# STM32H7B0 register map
File version: 2.3
CPU: CM7 r0p1, little endian, MPU, FPU, 4 interrupt priority bits
Registers are 32-bit, read-write, reset 0x0 unless marked. A register's access mark holds for its fields unless they carry their own. Offsets are from the block's base; [hi:lo] are bit positions; 'fields as' and 'values as' point back to an identical list.

## RCC (part 1 of 3) — Reset and clock control
Base 0x58024400
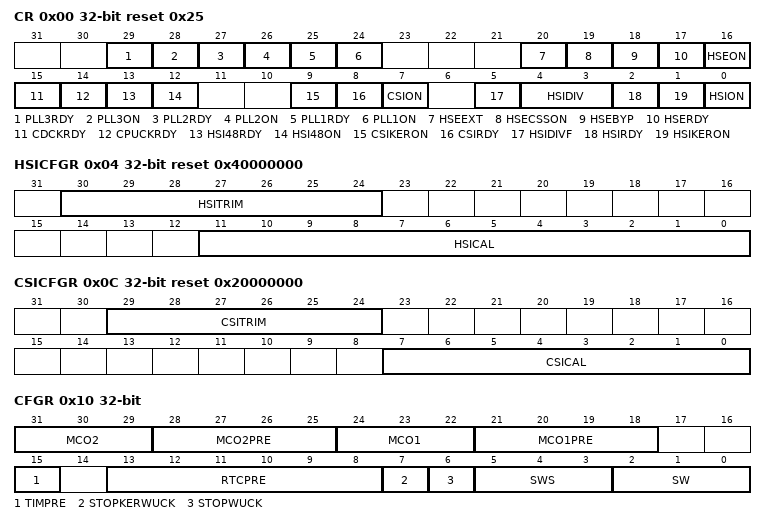
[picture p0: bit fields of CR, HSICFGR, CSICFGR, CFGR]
0x00 CR access per field reset 0x25
  [29] PLL3RDY ro — PLL3 clock ready flag Set by hardware to indicate that the PLL3 is locked.
    0=NotReady (Clock not ready); 1=Ready (Clock ready)
  [28] PLL3ON rw — PLL3 enable Set and cleared by software to enable PLL3. Cleared by hardware when entering Stop or Standby mode.
    0=Off (Clock Off); 1=On (Clock On)
  [27] PLL2RDY ro — PLL2 clock ready flag Set by hardware to indicate that the PLL2 is locked.
    0=NotReady (Clock not ready); 1=Ready (Clock ready)
  [26] PLL2ON rw — PLL2 enable Set and cleared by software to enable PLL2. Cleared by hardware when entering Stop or Standby mode.
    0=Off (Clock Off); 1=On (Clock On)
  [25] PLL1RDY ro — PLL1 clock ready flag Set by hardware to indicate that the PLL1 is locked.
    0=NotReady (Clock not ready); 1=Ready (Clock ready)
  [24] PLL1ON rw — PLL1 enable Set and cleared by software to enable PLL1. Cleared by hardware when entering Stop or Standby mode. Note that the hardware prevents writing this bit to 0, if the PLL1 output is used as the system clock.
    0=Off (Clock Off); 1=On (Clock On)
  [20] HSEEXT rw — external high speed clock type in Bypass mode Set and reset by software to select the external clock type (analog or digital). The external clock must be enabled with the HSEON bit to be used by the device. The HSEEXT bit can be written only if the HSE oscillator is disabled.
  [19] HSECSSON rw — HSE clock security system enable Set by software to enable clock security system on HSE. This bit is set only (disabled by a system reset or when the system enters in Standby mode). When HSECSSON is set, the clock detector is enabled by hardware when the HSE is ready and disabled by hardware if an oscillator failure is detected.
    0=Off (Clock Off); 1=On (Clock On)
  [18] HSEBYP rw — HSE clock bypass Set and cleared by software to bypass the oscillator with an external clock. The external clock must be enabled with the HSEON bit to be used by the device. The HSEBYP bit can be written only if the HSE oscillator is disabled.
    0=NotBypassed (HSE crystal oscillator not bypassed); 1=Bypassed (HSE crystal oscillator bypassed with external clock)
  [17] HSERDY ro — HSE clock ready flag Set by hardware to indicate that the HSE oscillator is stable.
    0=NotReady (Clock not ready); 1=Ready (Clock ready)
  [16] HSEON rw — HSE clock enable Set and cleared by software. Cleared by hardware to stop the HSE when entering Stop or Standby mode. This bit cannot be cleared if the HSE is used directly (via SW mux) as system clock, or if the HSE is selected as reference clock for PLL1 with PLL1 enabled (PLL1ON bit set to 1).
    0=Off (Clock Off); 1=On (Clock On)
  [15] CDCKRDY ro — CPU domain clocks ready flag Set by hardware to indicate that the following CPU domain clocks are available: APB1, APB2, AHB bus matrix.
    0=NotReady (Clock not ready); 1=Ready (Clock ready)
  [14] CPUCKRDY ro — CPU related clocks ready flag Set by hardware to indicate that the CPU related clocks (CPU, APB3, AXI bus matrix and related memories) are available.
    0=NotReady (Clock not ready); 1=Ready (Clock ready)
  [13] HSI48RDY ro — HSI48 clock ready flag Set by hardware to indicate that the HSI48 oscillator is stable.
    0=NotReady (Clock not ready); 1=Ready (Clock ready)
  [12] HSI48ON rw — HSI48 clock enable Set by software and cleared by software or by the hardware when the system enters to Stop or Standby mode.
    0=Off (Clock Off); 1=On (Clock On)
  [9] CSIKERON rw — CSI clock enable in Stop mode Set and reset by software to force the CSI to ON, even in Stop mode, in order to be quickly available as kernel clock for some peripherals. This bit has no effect on the value of CSION.
    0=Off (Clock Off); 1=On (Clock On)
  [8] CSIRDY ro — CSI clock ready flag Set by hardware to indicate that the CSI oscillator is stable. This bit is activated only if the RC is enabled by CSION (it is not activated if the CSI is enabled by CSIKERON or by a peripheral request).
    0=NotReady (Clock not ready); 1=Ready (Clock ready)
  [7] CSION rw — CSI clock enable Set and reset by software to enable/disable CSI clock for system and/or peripheral. Set by hardware to force the CSI to ON when the system leaves Stop mode, if STOPWUCK = 1 or STOPKERWUCK = 1. This bit cannot be cleared if the CSI is used directly (via SW mux) as system clock, or if the CSI is selected as reference clock for PLL1 with PLL1 enabled (PLL1ON bit set to 1).
    0=Off (Clock Off); 1=On (Clock On)
  [5] HSIDIVF ro — HSI divider flag Set and reset by hardware. As a write operation to HSIDIV has not an immediate effect on the frequency, this flag indicates the current status of the HSI divider. HSIDIVF goes immediately to 0 when HSIDIV value is changed, and is set back to 1 when the output frequency matches the value programmed into HSIDIV. clock setting is completed)
    0=NotPropagated (New HSIDIV ratio has not yet propagated to hsi_ck); 1=Propagated (HSIDIV ratio has propagated to hsi_ck)
  [4:3] HSIDIV rw — HSI clock divider Set and reset by software. These bits allow selecting a division ratio in order to configure the wanted HSI clock frequency. The HSIDIV cannot be changed if the HSI is selected as reference clock for at least one enabled PLL (PLLxON bit set to 1). In that case, the new HSIDIV value is ignored.
    0=Div1 (No division); 1=Div2 (Division by 2); 2=Div4 (Division by 4); 3=Div8 (Division by 8)
  [2] HSIRDY ro — HSI clock ready flag Set by hardware to indicate that the HSI oscillator is stable.
    0=NotReady (Clock not ready); 1=Ready (Clock ready)
  [1] HSIKERON rw — HSI clock enable in Stop mode Set and reset by software to force the HSI to ON, even in Stop mode, in order to be quickly available as kernel clock for peripherals. This bit has no effect on the value of HSION.
    0=Off (Clock Off); 1=On (Clock On)
  [0] HSION rw — HSI clock enable Set and cleared by software. Set by hardware to force the HSI to ON when the product leaves Stop mode, if STOPWUCK = 0 or STOPKERWUCK = 0. Set by hardware to force the HSI to ON when the product leaves Standby mode or in case of a failure of the HSE which is used as the system clock source. This bit cannot be cleared if the HSI is used directly (via SW mux) as system clock, or if the HSI is selected as reference clock for PLL1 with PLL1 enabled (PLL1ON bit set to 1).
    0=Off (Clock Off); 1=On (Clock On)
0x04 HSICFGR access per field reset 0x40000000 (reset mask 0xFFFFF000) — RCC HSI calibration register
  [30:24] HSITRIM rw — HSI clock trimming Set by software to adjust calibration. HSITRIM field is added to the engineering option bytes loaded during reset phase (FLASH_HSI_opt) in order to form the calibration trimming value. HSICAL=HSITRIM+FLASH_HSI_opt. Note: The reset value of the field is 0x40.
  [11:0] HSICAL ro — HSI clock calibration Set by hardware by option byte loading during system reset nreset. Adjusted by software through trimming bits HSITRIM. This field represents the sum of engineering option byte calibration value and HSITRIM bits value.
0x08 CRRCR ro (reset mask 0xFFFFF000) — RCC clock recovery RC register
  [9:0] HSI48CAL — Internal RC 48 MHz clock calibration Set by hardware by option byte loading during system reset nreset. Read-only.
0x0C CSICFGR access per field reset 0x20000000 (reset mask 0xFFFFF000) — RCC CSI calibration register
  [29:24] CSITRIM rw — CSI clock trimming Set by software to adjust calibration. CSITRIM field is added to the engineering option bytes loaded during reset phase (FLASH_CSI_opt) in order to form the calibration trimming value. CSICAL=CSITRIM+FLASH_CSI_opt. Note: The reset value of the field is 0x20.
  [7:0] CSICAL ro — CSI clock calibration Set by hardware by option byte loading during system reset nreset. Adjusted by software through trimming bits CSITRIM. This field represents the sum of engineering option byte calibration value and CSITRIM bits value.
0x10 CFGR access per field
  [31:29] MCO2 rw — microcontroller clock output 2 Set and cleared by software. Clock source selection may generate glitches on MCO2. It is highly recommended to configure these bits only after reset, before enabling the external oscillators and the PLLs. others: reserved
    0=SYSCLK (System clock selected for micro-controller clock output); 1=PLL2_P (pll2_p selected for micro-controller clock output); 2=HSE (HSE selected for micro-controller clock output); 3=PLL1_P (pll1_p selected for micro-controller clock output); 4=CSI (CSI selected for micro-controller clock output); 5=LSI (LSI selected for micro-controller clock output)
  [28:25] MCO2PRE rw — MCO2 prescaler Set and cleared by software to configure the prescaler of the MCO2. Modification of this prescaler may generate glitches on MCO2. It is highly recommended to change this prescaler only after reset, before enabling the external oscillators and the PLLs. ...
  [24:22] MCO1 rw — Microcontroller clock output 1 Set and cleared by software. Clock source selection may generate glitches on MCO1. It is highly recommended to configure these bits only after reset, before enabling the external oscillators and the PLLs. others: reserved
    0=HSI (HSI selected for micro-controller clock output); 1=LSE (LSE selected for micro-controller clock output); 2=HSE (HSE selected for micro-controller clock output); 3=PLL1_Q (pll1_q selected for micro-controller clock output); 4=HSI48 (HSI48 selected for micro-controller clock output)
  [21:18] MCO1PRE rw — MCO1 prescaler Set and cleared by software to configure the prescaler of the MCO1. Modification of this prescaler may generate glitches on MCO1. It is highly recommended to change this prescaler only after reset, before enabling the external oscillators and the PLLs. ...
  [15] TIMPRE rw — timers clocks prescaler selection This bit is set and reset by software to control the clock frequency of all the timers connected to APB1 and APB2 domains. Refer to for more details.
    0=DefaultX2 (Timer kernel clock equal to 2x pclk by default); 1=DefaultX4 (Timer kernel clock equal to 4x pclk by default)
  [13:8] RTCPRE rw — HSE division factor for RTC clock Set and cleared by software to divide the HSE to generate a clock for RTC. Caution: The software must set these bits correctly to ensure that the clock supplied to the RTC is lower than 1MHz. These bits must be configured if needed before selecting the RTC clock source. ...
  [7] STOPKERWUCK rw — kernel clock selection after a wake up from system Stop Set and reset by software to select the kernel wakeup clock from system Stop. See for details.
    0=HSI (HSI selected as wake up clock from system Stop); 1=CSI (CSI selected as wake up clock from system Stop)
  [6] STOPWUCK rw — system clock selection after a wake up from system Stop Set and reset by software to select the system wakeup clock from system Stop. The selected clock is also used as emergency clock for the clock security system (CSS) on HSE. See for details. STOPWUCK must not be modified when CSS is enabled (by HSECSSON bit) and the system clock is HSE (SWS=10) or a switch on HSE is requested (SW=10).
    values as STOPKERWUCK
  [5:3] SWS ro — system clock switch status Set and reset by hardware to indicate which clock source is used as system clock. others: reserved
    0=HSI (HSI oscillator used as system clock); 1=CSI (CSI oscillator used as system clock); 2=HSE (HSE oscillator used as system clock); 3=PLL1 (PLL1 used as system clock)
  [2:0] SW rw — system clock and trace clock switch Set and reset by software to select system clock and trace clock sources (sys_ck and traceclk). Set by hardware in order to: force the selection of the HSI or CSI (depending on STOPWUCK selection) when leaving a system Stop mode force the selection of the HSI in case of failure of the HSE when used directly or indirectly as system clock others: reserved
    0=HSI (HSI selected as system clock); 1=CSI (CSI selected as system clock); 2=HSE (HSE selected as system clock); 3=PLL1 (PLL1 selected as system clock)
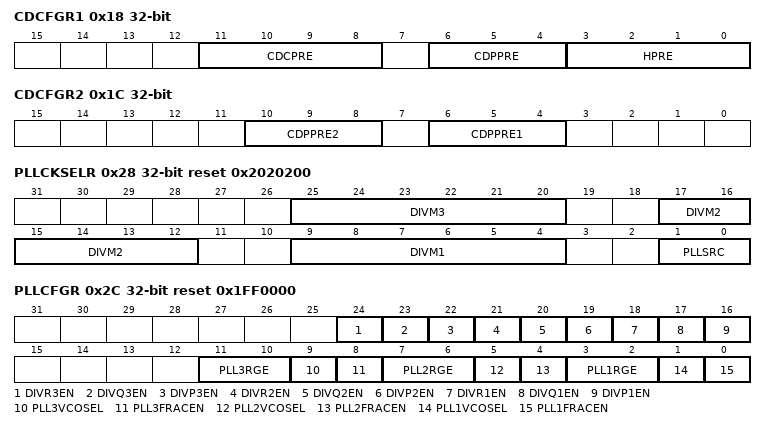
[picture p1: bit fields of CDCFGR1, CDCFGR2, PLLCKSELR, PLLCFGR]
0x18 CDCFGR1
  [11:8] CDCPRE — CPU domain core prescaler Set and reset by software to control the CPU domain CPU clock division factor. Changing this division ratio has an impact on the frequency of the CPU clock and all bus matrix clocks. After changing this prescaler value, it takes up to 16 periods of the slowest APB clock before the new division ratio is taken into account. The application can check if the new division factor is taken into account by reading back this register. 0xxx: sys_ck not divided (default after reset)
    8=Div2 (sys_ck divided by 2); 9=Div4 (sys_ck divided by 4); 10=Div8 (sys_ck divided by 8); 11=Div16 (sys_ck divided by 16); 12=Div64 (sys_ck divided by 64); 13=Div128 (sys_ck divided by 128); 14=Div256 (sys_ck divided by 256); 15=Div512 (sys_ck divided by 512); other=Div1 (sys_ck not divided)
  [6:4] CDPPRE — CPU domain APB3 prescaler Set and reset by software to control the division factor of rcc_pclk3. The clock is divided by the new prescaler factor from 1 to 16 cycles of rcc_hclk3 after CDPPRE write. 0xx: rcc_pclk3 = rcc_hclk3 (default after reset)
    4=Div2 (rcc_hclk divided by 2); 5=Div4 (rcc_hclk divided by 4); 6=Div8 (rcc_hclk divided by 8); 7=Div16 (rcc_hclk divided by 16); other=Div1 (rcc_hclk not divided)
  [3:0] HPRE — CPU domain AHB prescaler Set and reset by software to control the division factor of rcc_hclk3 and rcc_aclk. Changing this division ratio has an impact on the frequency of all bus matrix clocks. 0xxx: rcc_hclk3 = sys_cdcpre_ck (default after reset) Note: The clocks are divided by the new prescaler factor from1 to 16 periods of the slowest APB clock among rcc_pclk[4:1] after HPRE update. Note: Note also that rcc_hclk3 = rcc_aclk.
    values as CDCPRE
0x1C CDCFGR2
  [10:8] CDPPRE2 — CPU domain APB2 prescaler Set and reset by software to control the CPU domain APB2 clock division factor. The clock is divided by the new prescaler factor from 1 to 16 cycles of rcc_hclk1 after CDPPRE2 write. 0xx: rcc_pclk2 = rcc_hclk1 (default after reset)
    values as CDCFGR1.CDPPRE
  [6:4] CDPPRE1 — CPU domain APB1 prescaler Set and reset by software to control the CPU domain APB1 clock division factor. The clock is divided by the new prescaler factor from 1 to 16 cycles of rcc_hclk1 after CDPPRE1 write. 0xx: rcc_pclk1 = rcc_hclk1 (default after reset)
    values as CDCFGR1.CDPPRE
0x20 SRDCFGR
  [6:4] SRDPPRE — SmartRun domain APB4 prescaler Set and reset by software to control the SmartRun domain APB4 clock division factor. The clock is divided by the new prescaler factor from 1 to 16 cycles of rcc_hclk4 after SRDPPRE write. 0xx: rcc_pclk4 = rcc_hclk4 (default after reset)
0x28 PLLCKSELR reset 0x2020200
  [25:20] DIVM3 — prescaler for PLL3 Set and cleared by software to configure the prescaler of the PLL3. The hardware does not allow any modification of this prescaler when PLL3 is enabled (PLL3ON=1). In order to save power when PLL3 is not used, the value of DIVM3 must be set to 0. ... ...
  [17:12] DIVM2 — prescaler for PLL2 Set and cleared by software to configure the prescaler of the PLL2. The hardware does not allow any modification of this prescaler when PLL2 is enabled (PLL2ON=1). In order to save power when PLL2 is not used, the value of DIVM2 must be set to 0. ... ...
  [9:4] DIVM1 — prescaler for PLL1 Set and cleared by software to configure the prescaler of the PLL1. The hardware does not allow any modification of this prescaler when PLL1 is enabled (PLL1ON=1). In order to save power when PLL1 is not used, the value of DIVM1 must be set to 0. ... ...
  [1:0] PLLSRC — DIVMx and PLLs clock source selection Set and reset by software to select the PLL clock source. These bits can be written only when all PLLs are disabled. In order to save power, when no PLL is used, the value of PLLSRC must be set to '11'.
    0=HSI (HSI selected as PLL clock); 1=CSI (CSI selected as PLL clock); 2=HSE (HSE selected as PLL clock); 3=None (No clock sent to DIVMx dividers and PLLs)
0x2C PLLCFGR reset 0x1FF0000
  [24] DIVR3EN — PLL3 DIVR divider output enable Set and reset by software to enable the pll3_r_ck output of the PLL3. To save power, DIVR3EN and DIVR3 bits must be set to 0 when the pll3_r_ck is not used. This bit can be written only when the PLL3 is disabled (PLL3ON = 0 and PLL3RDY = 0).
    0=Disabled (Clock ouput is disabled); 1=Enabled (Clock output is enabled)
  [23] DIVQ3EN — PLL3 DIVQ divider output enable Set and reset by software to enable the pll3_q_ck output of the PLL3. To save power, DIVR3EN and DIVR3 bits must be set to 0 when the pll3_r_ck is not used. This bit can be written only when the PLL3 is disabled (PLL3ON = 0 and PLL3RDY = 0).
    values as DIVR3EN
  [22] DIVP3EN — PLL3 DIVP divider output enable Set and reset by software to enable the pll3_p_ck output of the PLL3. This bit can be written only when the PLL3 is disabled (PLL3ON = 0 and PLL3RDY = 0). To save power, DIVR3EN and DIVR3 bits must be set to 0 when the pll3_r_ck is not used.
    values as DIVR3EN
  [21] DIVR2EN — PLL2 DIVR divider output enable Set and reset by software to enable the pll2_r_ck output of the PLL2. To save power, DIVR3EN and DIVR3 bits must be set to 0 when the pll3_r_ck is not used. This bit can be written only when the PLL2 is disabled (PLL2ON = 0 and PLL2RDY = 0).
    values as DIVR3EN
  [20] DIVQ2EN — PLL2 DIVQ divider output enable Set and reset by software to enable the pll2_q_ck output of the PLL2. To save power, DIVR3EN and DIVR3 bits must be set to 0 when the pll3_r_ck is not used. This bit can be written only when the PLL2 is disabled (PLL2ON = 0 and PLL2RDY = 0).
    values as DIVR3EN
  [19] DIVP2EN — PLL2 DIVP divider output enable Set and reset by software to enable the pll2_p_ck output of the PLL2. This bit can be written only when the PLL2 is disabled (PLL2ON = 0 and PLL2RDY = 0). To save power, DIVR3EN and DIVR3 bits must be set to 0 when the pll3_r_ck is not used.
    values as DIVR3EN
  [18] DIVR1EN — PLL1 DIVR divider output enable Set and reset by software to enable the pll1_r_ck output of the PLL1. To save power, DIVR3EN and DIVR3 bits must be set to 0 when the pll3_r_ck is not used. This bit can be written only when the PLL1 is disabled (PLL1ON = 0 and PLL1RDY = 0).
    values as DIVR3EN
  [17] DIVQ1EN — PLL1 DIVQ divider output enable Set and reset by software to enable the pll1_q_ck output of the PLL1. In order to save power, when the pll1_q_ck output of the PLL1 is not used, the pll1_q_ck must be disabled. This bit can be written only when the PLL1 is disabled (PLL1ON = 0 and PLL1RDY = 0).
    values as DIVR3EN
  [16] DIVP1EN — PLL1 DIVP divider output enable Set and reset by software to enable the pll1_p_ck output of the PLL1. This bit can be written only when the PLL1 is disabled (PLL1ON = 0 and PLL1RDY = 0). In order to save power, when the pll1_p_ck output of the PLL1 is not used, the pll1_p_ck must be disabled.
    values as DIVR3EN
  [11:10] PLL3RGE — PLL3 input frequency range Set and reset by software to select the proper reference frequency range used for PLL3. These bits must be written before enabling the PLL3.
    0=Range1 (Frequency is between 1 and 2 MHz); 1=Range2 (Frequency is between 2 and 4 MHz); 2=Range4 (Frequency is between 4 and 8 MHz); 3=Range8 (Frequency is between 8 and 16 MHz)
  [9] PLL3VCOSEL — PLL3 VCO selection Set and reset by software to select the proper VCO frequency range used for PLL3. This bit must be written before enabling the PLL3.
    0=WideVCO (VCO frequency range 192 to 836 MHz); 1=MediumVCO (VCO frequency range 150 to 420 MHz)
  [8] PLL3FRACEN — PLL3 fractional latch enable Set and reset by software to latch the content of FRACN3 into the sigma-delta modulator. In order to latch the FRACN3 value into the sigma-delta modulator, PLL3FRACEN must be set to 0, then set to 1. The transition 0 to 1 transfers the content of FRACN3 into the modulator. Refer to for additional information.
    0=Reset latch to tranfer FRACN to the Sigma-Delta modulator; 1=Set (Set latch to tranfer FRACN to the Sigma-Delta modulator)
  [7:6] PLL2RGE — PLL2 input frequency range Set and reset by software to select the proper reference frequency range used for PLL2. These bits must be written before enabling the PLL2.
    values as PLL3RGE
  [5] PLL2VCOSEL — PLL2 VCO selection Set and reset by software to select the proper VCO frequency range used for PLL2. This bit must be written before enabling the PLL2.
    values as PLL3VCOSEL
  [4] PLL2FRACEN — PLL2 fractional latch enable Set and reset by software to latch the content of FRACN2 into the sigma-delta modulator. In order to latch the FRACN2 value into the sigma-delta modulator, PLL2FRACEN must be set to 0, then set to 1. The transition 0 to 1 transfers the content of FRACN2 into the modulator. Refer to for additional information.
    values as PLL3FRACEN
  [3:2] PLL1RGE — PLL1 input frequency range Set and reset by software to select the proper reference frequency range used for PLL1. This bit must be written before enabling the PLL1.
    values as PLL3RGE
  [1] PLL1VCOSEL — PLL1 VCO selection Set and reset by software to select the proper VCO frequency range used for PLL1. These bits must be written before enabling the PLL1.
    values as PLL3VCOSEL
  [0] PLL1FRACEN — PLL1 fractional latch enable Set and reset by software to latch the content of FRACN1 into the sigma-delta modulator. In order to latch the FRACN1 value into the sigma-delta modulator, PLL1FRACEN must be set to 0, then set to 1. The transition 0 to 1 transfers the content of FRACN1 into the modulator. Refer to for additional information.
    values as PLL3FRACEN
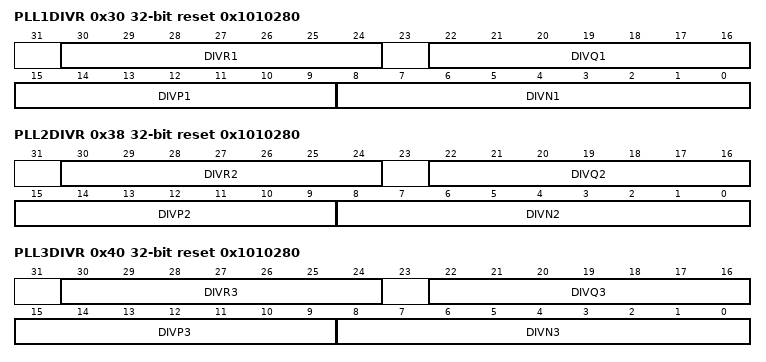
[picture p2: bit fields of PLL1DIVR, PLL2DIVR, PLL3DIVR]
0x30 PLL1DIVR reset 0x1010280
  [30:24] DIVR1 — PLL1 DIVR division factor Set and reset by software to control the frequency of the pll1_r_ck clock. These bits can be written only when the PLL1 is disabled (PLL1ON = 0 and PLL1RDY = 0). ...
  [22:16] DIVQ1 — PLL1 DIVQ division factor Set and reset by software to control the frequency of the pll1_q_ck clock. These bits can be written only when the PLL1 is disabled (PLL1ON = 0 and PLL1RDY = 0). ...
  [15:9] DIVP1 — PLL1 DIVP division factor Set and reset by software to control the frequency of the pll1_p_ck clock. These bits can be written only when the PLL1 is disabled (PLL1ON = 0 and PLL1RDY = 0). Note that odd division factors are not allowed. ...
    0=Div1 (pll_p_ck = vco_ck); 1=Div2 (pll_p_ck = vco_ck / 2); 3=Div4 (pll_p_ck = vco_ck / 4); 5=Div6 (pll_p_ck = vco_ck / 6); 7=Div8 (pll_p_ck = vco_ck / 8); 9=Div10 (pll_p_ck = vco_ck / 10); 11=Div12 (pll_p_ck = vco_ck / 12); 13=Div14 (pll_p_ck = vco_ck / 14); 15=Div16 (pll_p_ck = vco_ck / 16); 17=Div18 (pll_p_ck = vco_ck / 18); 19=Div20 (pll_p_ck = vco_ck / 20); 21=Div22 (pll_p_ck = vco_ck / 22); 23=Div24 (pll_p_ck = vco_ck / 24); 25=Div26 (pll_p_ck = vco_ck / 26); 27=Div28 (pll_p_ck = vco_ck / 28); 29=Div30 (pll_p_ck = vco_ck / 30); 31=Div32 (pll_p_ck = vco_ck / 32); 33=Div34 (pll_p_ck = vco_ck / 34); 35=Div36 (pll_p_ck = vco_ck / 36); 37=Div38 (pll_p_ck = vco_ck / 38); 39=Div40 (pll_p_ck = vco_ck / 40); 41=Div42 (pll_p_ck = vco_ck / 42); 43=Div44 (pll_p_ck = vco_ck / 44); 45=Div46 (pll_p_ck = vco_ck / 46); 47=Div48 (pll_p_ck = vco_ck / 48); 49=Div50 (pll_p_ck = vco_ck / 50); 51=Div52 (pll_p_ck = vco_ck / 52); 53=Div54 (pll_p_ck = vco_ck / 54); 55=Div56 (pll_p_ck = vco_ck / 56); 57=Div58 (pll_p_ck = vco_ck / 58); 59=Div60 (pll_p_ck = vco_ck / 60); 61=Div62 (pll_p_ck = vco_ck / 62); 63=Div64 (pll_p_ck = vco_ck / 64); 65=Div66 (pll_p_ck = vco_ck / 66); 67=Div68 (pll_p_ck = vco_ck / 68); 69=Div70 (pll_p_ck = vco_ck / 70); 71=Div72 (pll_p_ck = vco_ck / 72); 73=Div74 (pll_p_ck = vco_ck / 74); 75=Div76 (pll_p_ck = vco_ck / 76); 77=Div78 (pll_p_ck = vco_ck / 78); 79=Div80 (pll_p_ck = vco_ck / 80); 81=Div82 (pll_p_ck = vco_ck / 82); 83=Div84 (pll_p_ck = vco_ck / 84); 85=Div86 (pll_p_ck = vco_ck / 86); 87=Div88 (pll_p_ck = vco_ck / 88); 89=Div90 (pll_p_ck = vco_ck / 90); 91=Div92 (pll_p_ck = vco_ck / 92); 93=Div94 (pll_p_ck = vco_ck / 94); 95=Div96 (pll_p_ck = vco_ck / 96); 97=Div98 (pll_p_ck = vco_ck / 98); 99=Div100 (pll_p_ck = vco_ck / 100); 101=Div102 (pll_p_ck = vco_ck / 102); 103=Div104 (pll_p_ck = vco_ck / 104); 105=Div106 (pll_p_ck = vco_ck / 106); 107=Div108 (pll_p_ck = vco_ck / 108); 109=Div110 (pll_p_ck = vco_ck / 110); 111=Div112 (pll_p_ck = vco_ck / 112); 113=Div114 (pll_p_ck = vco_ck / 114); 115=Div116 (pll_p_ck = vco_ck / 116); 117=Div118 (pll_p_ck = vco_ck / 118); 119=Div120 (pll_p_ck = vco_ck / 120); 121=Div122 (pll_p_ck = vco_ck / 122); 123=Div124 (pll_p_ck = vco_ck / 124); 125=Div126 (pll_p_ck = vco_ck / 126); 127=Div128 (pll_p_ck = vco_ck / 128)
  [8:0] DIVN1 range 3..511 — multiplication factor for PLL1 VCO Set and reset by software to control the multiplication factor of the VCO. These bits can be written only when the PLL is disabled (PLL1ON = PLL1RDY = 0). ..........: not used ... ... Others: wrong configurations The software must set correctly these bits to insure that the VCO output frequency is between its valid frequency range, that is: 128 to 560MHz if PLL1VCOSEL = 0 150 to 420MHz if PLL1VCOSEL = 1 VCO output frequency = Fref1_ck x DIVN1, when fractional value 0 has been loaded into FRACN1, with: DIVN1 between 8 and 420 The input frequency Fref1_ck must be between 1 and 16MHz.
0x34 PLL1FRACR
  [15:3] FRACN1 — fractional part of the multiplication factor for PLL1 VCO Set and reset by software to control the fractional part of the multiplication factor of the VCO. These bits can be written at any time, allowing dynamic fine-tuning of the PLL1 VCO. The software must set correctly these bits to insure that the VCO output frequency is between its valid frequency range, that is: 128 to 560MHz if PLL1VCOSEL = 0 150 to 420MHz if PLL1VCOSEL = 1 VCO output frequency = Fref1_ck x (DIVN1 + (FRACN1 / 213)), with DIVN1 between 8 and 420 FRACN1 can be between 0 and 213- 1 The input frequency Fref1_ck must be between 1 and 16 MHz. To change the FRACN value on-the-fly even if the PLL is enabled, the application must proceed as follows: Set the bit PLL1FRACEN to 0. Write the new fractional value into FRACN1. Set the bit PLL1FRACEN to 1.
0x38 PLL2DIVR reset 0x1010280
  [30:24] DIVR2 — PLL2 DIVR division factor Set and reset by software to control the frequency of the pll2_r_ck clock. These bits can be written only when the PLL2 is disabled (PLL2ON = PLL2RDY = 0). ...
  [22:16] DIVQ2 — PLL2 DIVQ division factor Set and reset by software to control the frequency of the pll2_q_ck clock. These bits can be written only when the PLL2 is disabled (PLL2ON = PLL2RDY = 0). ...
  [15:9] DIVP2 — PLL2 DIVP division factor Set and reset by software to control the frequency of the pll2_p_ck clock. These bits can be written only when the PLL2 is disabled (PLL2ON = PLL2RDY = 0). ...
  [8:0] DIVN2 range 3..511 — multiplication factor for PLL2 VCO Set and reset by software to control the multiplication factor of the VCO. These bits can be written only when the PLL is disabled (PLL2ON = PLL2RDY = 0). ..........: not used ... ... Others: wrong configurations The software must set correctly these bits to insure that the VCO output frequency is between its valid frequency range, that is: 128 to 560MHz if PLL2VCOSEL = 0 150 to 420MHz if PLL2VCOSEL = 1 VCO output frequency = Fref2_ck x DIVN2, when fractional value 0 has been loaded into FRACN2, with DIVN2 between 8 and 420 The input frequency Fref2_ck must be between 1 and 16MHz.
0x3C PLL2FRACR
  [15:3] FRACN2 — fractional part of the multiplication factor for PLL2 VCO Set and reset by software to control the fractional part of the multiplication factor of the VCO. These bits can be written at any time, allowing dynamic fine-tuning of the PLL2 VCO. The software must set correctly these bits to insure that the VCO output frequency is between its valid frequency range, that is: 128 to 560MHz if PLL2VCOSEL = 0 150 to 420MHz if PLL2VCOSEL = 1 VCO output frequency = Fref2_ck x (DIVN2 + (FRACN2 / 213)), with DIVN2 between 8 and 420 FRACN2 can be between 0 and 213 - 1 The input frequency Fref2_ck must be between 1 and 16 MHz. In order to change the FRACN value on-the-fly even if the PLL is enabled, the application must proceed as follows: Set the bit PLL2FRACEN to 0. Write the new fractional value into FRACN2. Set the bit PLL2FRACEN to 1.
0x40 PLL3DIVR reset 0x1010280
  [30:24] DIVR3 — PLL3 DIVR division factor Set and reset by software to control the frequency of the pll3_r_ck clock. These bits can be written only when the PLL3 is disabled (PLL3ON = PLL3RDY = 0). ...
  [22:16] DIVQ3 — PLL3 DIVQ division factor Set and reset by software to control the frequency of the pll3_q_ck clock. These bits can be written only when the PLL3 is disabled (PLL3ON = PLL3RDY = 0). ...
  [15:9] DIVP3 — PLL3 DIVP division factor Set and reset by software to control the frequency of the pll3_p_ck clock. These bits can be written only when the PLL3 is disabled (PLL3ON = PLL3RDY = 0). ...
  [8:0] DIVN3 range 3..511 — Multiplication factor for PLL3 VCO Set and reset by software to control the multiplication factor of the VCO. These bits can be written only when the PLL is disabled (PLL3ON = PLL3RDY = 0). ...........: not used ... ... Others: wrong configurations The software must set correctly these bits to insure that the VCO output frequency is between its valid frequency range, that is: 128 to 560MHz if PLL3VCOSEL = 0 150 to 420MHz if PLL3VCOSEL = 1 VCO output frequency = Fref3_ck x DIVN3, when fractional value 0 has been loaded into FRACN3, with: DIVN3 between 8 and 420 The input frequency Fref3_ck must be between 1 and 16MHz
0x44 PLL3FRACR
  [15:3] FRACN3 — fractional part of the multiplication factor for PLL3 VCO Set and reset by software to control the fractional part of the multiplication factor of the VCO. These bits can be written at any time, allowing dynamic fine-tuning of the PLL3 VCO. The software must set correctly these bits to insure that the VCO output frequency is between its valid frequency range, that is: 128 to 560MHz if PLL3VCOSEL = 0 150 to 420MHz if PLL3VCOSEL = 1 VCO output frequency = Fref3_ck x (DIVN3 + (FRACN3 / 213)), with DIVN3 between 8 and 420 FRACN3 can be between 0 and 213 - 1 The input frequency Fref3_ck must be between 1 and 16 MHz. In order to change the FRACN value on-the-fly even if the PLL is enabled, the application must proceed as follows: Set the bit PLL1FRACEN to 0. Write the new fractional value into FRACN1. Set the bit PLL1FRACEN to 1.
